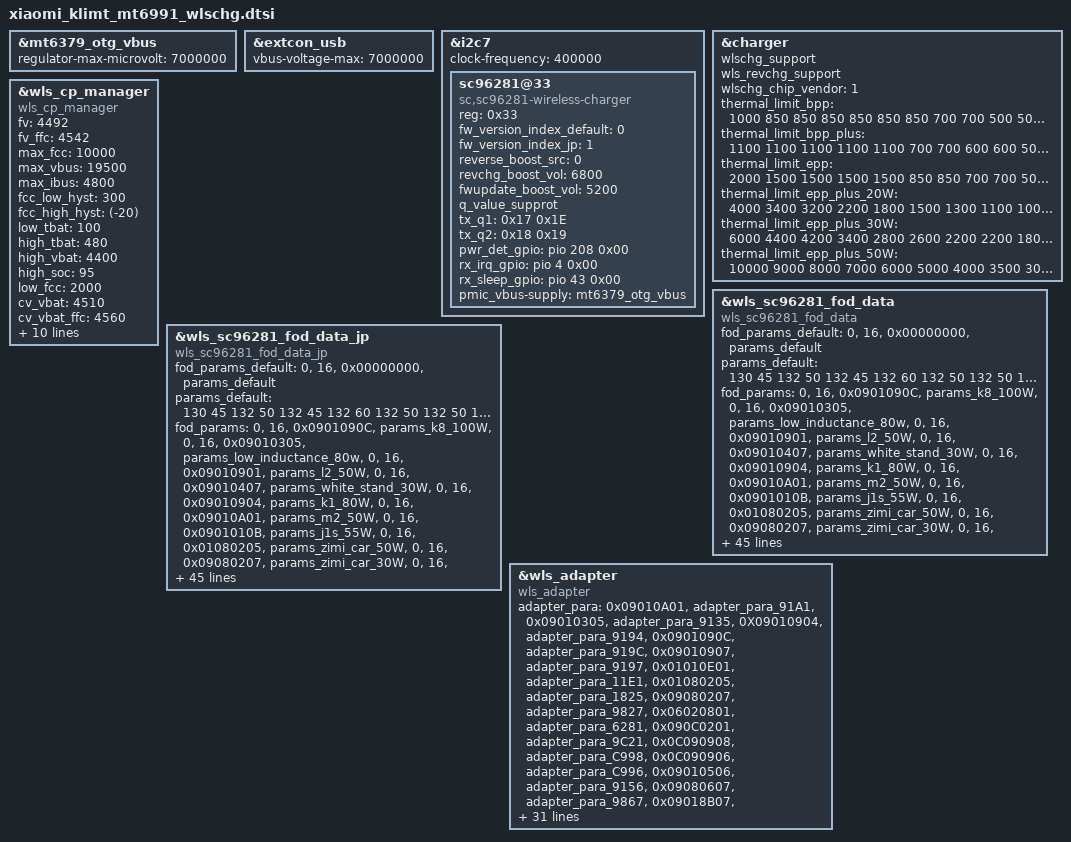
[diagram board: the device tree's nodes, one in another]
&mt6379_otg_vbus {
	regulator-max-microvolt = <7000000>;
};

&extcon_usb {
	vbus-voltage-max = <7000000>;
};

&i2c7 {
	clock-frequency = <400000>;
	sc96281@33{
		compatible = "sc,sc96281-wireless-charger";
		reg = <0x33>;
		fw_version_index_default = <0>;
		fw_version_index_jp = <1>;
		reverse_boost_src = <0>;
		revchg_boost_vol = <6800>;
		fwupdate_boost_vol = <5200>;
		q_value_supprot;
		tx_q1 = /bits/ 8 <0x17 0x1E>;
		tx_q2 = /bits/ 8 <0x18 0x19>;

		//support_hall = <0>;
		//rx_role = <0>;

		pwr_det_gpio = <&pio 208 0x00>;
		rx_irq_gpio = <&pio 4 0x00>;
		rx_sleep_gpio = <&pio 43 0x00>;
		pmic_vbus-supply = <&mt6379_otg_vbus>;
	};
};

&charger {
	wlschg_support;
	wls_revchg_support;
	wlschg_chip_vendor = <1>;
	/* wls thermal config */
	thermal_limit_bpp = <1000 850 850 850 850 850 850 700 700 500 500 500 500 500 400 300>;
	thermal_limit_bpp_plus = <1100 1100 1100 1100 1100 700 700 600 600 500 500 500 500 500 400 300>;
	thermal_limit_epp = <2000 1500 1500 1500 1500 850 850 700 700 500 500 500 500 500 400 300>;
	thermal_limit_epp_plus_20W = <4000 3400 3200 2200 1800 1500 1300 1100 1000 800 700 600 500 500 400 300>;
	thermal_limit_epp_plus_30W = <6000 4400 4200 3400 2800 2600 2200 2200 1800 1100 1000 800 700 600 500 400>;
	thermal_limit_epp_plus_50W = <10000 9000 8000 7000 6000 5000 4000 3500 3000 2500 2000 1500 1000 800 500 400>;
};

&wls_cp_manager {
	compatible = "wls_cp_manager";
	fv = <4492>;
	fv_ffc = <4542>;
	max_fcc = <10000>;
	max_vbus = <19500>;
	max_ibus = <4800>;
	fcc_low_hyst = <300>;
	fcc_high_hyst = <(-20)>;
	low_tbat = <100>;
	high_tbat = <480>;
	high_vbat = <4400>;
	high_soc = <95>;
	low_fcc = <2000>;
	cv_vbat = <4510>;
	cv_vbat_ffc = <4560>;
	cv_ibat = <1200>;
	vbus_low_gap_div = <500>;
	vbus_high_gap_div = <600>;
	wls_cm_ibus_gap = <600>;
	switch2_1_enter = <6000>;
	switch2_1_exit = <8000>;
	support_pmic_parachg;
	pmic_parachg_icl = <100>;
	max_curr_duration_4_1 = <240>;
	max_curr_duration_2_1 = <90>;
};

&wls_sc96281_fod_data {
	compatible = "wls_sc96281_fod_data";
	fod_params_default =
		"0", "16", "0x00000000", "params_default";
	params_default = /bits/ 8 <
		130  45
		132  50
		132  45
		132  60
		132  50
		132  50
		130  99
		130  99
		130  99
		130  99
		130  99
		130  99
		130  99
		130  99
		130  99
		130  99
	>;

	/* type, length, uuid, params */
	fod_params =
		"0", "16", "0x0901090C", "params_k8_100W",
		"0", "16", "0x09010305", "params_low_inductance_80w",
		"0", "16", "0x09010901", "params_l2_50W",
		"0", "16", "0x09010407", "params_white_stand_30W",
		"0", "16", "0x09010904", "params_k1_80W",
		"0", "16", "0x09010A01", "params_m2_50W",
		"0", "16", "0x0901010B", "params_j1s_55W",
		"0", "16", "0x01080205", "params_zimi_car_50W",
		"0", "16", "0x09080207", "params_zimi_car_30W",
		"0", "16", "0x09010907", "params_redmi_disc_30W",
		"0", "16", "0x09080108", "params_zimi_20W",
		"0", "16", "0x09010506", "params_moving_20W",
		"0", "16", "0x09010A07", "params_double_coil_30W",
		"0", "16", "0x06010101", "params_white_20W",
		"0", "16", "0x0C090908", "params_multcoil_20W",
		"0", "16", "0x06020801", "params_zimi_car_20W",
		"0", "16", "0x09080607", "params_bluetooth_30W",
		"0", "16", "0x07030801", "params_power_bank_30W";

	/* gain, offset */
	params_k8_100W = /bits/ 8 <
		120	50
		120	55
		121	55
		121	55
		121	65
		122	70
		122	80
		123	80
		125	85
		127	85
		255	127
		154	100
		144	80
		134	60
		134	60
		134	60
	>;

	params_low_inductance_80w = /bits/ 8 <
		118	45
		118	40
		118	40
		118	40
		118	40
		118	40
		119	40
		120	40
		120	40
		120	40
		115	30
		115	30
		115	30
		116	40
		117	40
		117	40
	>;

	params_l2_50W = /bits/ 8 <
		125	45
		125	45
		124	40
		124	55
		124	55
		124	55
		124	55
		123	50
		123	55
		123	55
		255	127
		154	100
		144	80
		134	60
		134	60
		134	60
	>;

	params_white_stand_30W = /bits/ 8 <
		125	65
		125	65
		125	60
		125	60
		125	60
		125	60
		125	70
		125	70
		125	70
		125	75
		255	127
		154	100
		144	80
		134	60
		134	60
		134	60
	>;

	params_k1_80W = /bits/ 8 <
		125	65
		125	65
		125	60
		125	60
		125	60
		125	60
		126	75
		128	75
		128	75
		129	75
		255	127
		154	100
		144	80
		134	60
		134	60
		134	60
	>;

	params_m2_50W = /bits/ 8 <
		125	55
		125	55
		124	50
		123	45
		123	40
		123	40
		122	40
		122	35
		121	35
		121	35
		253	127
		150	90
		140	60
		137	60
		137	60
		137	60
	>;

	params_j1s_55W = /bits/ 8 <
		125	45
		125	45
		125	50
		125	55
		125	60
		125	60
		124	55
		124	55
		124	55
		124	55
		255	127
		154	100
		144	80
		134	60
		134	60
		134	60
	>;

	params_zimi_car_50W = /bits/ 8 <
		120  25
		120  10
		120  15
		120  20
		102  19
		111  25
		123  25
		123  30
		129  15
		124  20
		126  20
		126  20
		112  40
		112  40
		112  40
		112  40
	>;

	params_zimi_car_30W = /bits/ 8 <
		128  40
		127  34
		127  34
		127  34
		126  34
		125  38
		125  38
		124  41
		124  43
		123  40
		126  36
		126  36
		128  40
		128  40
		128  40
		128  40
	>;

	params_redmi_disc_30W = /bits/ 8 <
		125	55
		125	55
		125	55
		125	55
		125	50
		125	50
		126	60
		127	55
		128	70
		129	70
		255	127
		154	100
		144	80
		134	60
		134	60
		134	60
	>;

	params_zimi_20W = /bits/ 8 <
		120  30
		124  45
		127  40
		127  40
		127  40
		127  40
		128  40
		127  40
		128  40
		128  40
		128  40
		128  40
		128  40
		128  40
		128  40
		128  40
	>;

	params_moving_20W = /bits/ 8 <
		122  30
		121  32
		123  22
		126  21
		126  27
		126  27
		122  24
		122  24
		122  24
		122  24
		122  24
		122  24
		122  24
		122  24
		122  24
		122  24
	>;

	params_double_coil_30W = /bits/ 8 <
		118	45
		118	45
		118	45
		118	35
		118	40
		118	40
		120	50
		121	60
		121	60
		121	60
		255	127
		154	100
		144	80
		134	60
		134	60
		134	60
	>;

	params_power_bank_30W = /bits/ 8 <
		120  25
		120  10
		120  15
		120  24
		102  29
		111  35
		123  35
		123  40
		129  25
		124  40
		126  40
		126  40
		112  40
		112  40
		112  40
		112  40
	>;

	params_white_20W = /bits/ 8 <
		120	50
		120	55
		121	55
		121	55
		121	65
		122	70
		122	80
		123	80
		125	85
		127	85
		255	127
		154	100
		144	80
		134	60
		134	60
		134	60
	>;

	params_multcoil_20W = /bits/ 8 <
		120  25
		120  10
		120  15
		120  20
		102  19
		111  25
		123  25
		123  30
		129  15
		124  20
		126  20
		126  20
		112  40
		112  40
		112  40
		112  40
	>;

	params_zimi_car_20W = /bits/ 8 <
		120  25
		120  10
		120  15
		120  20
		102  19
		111  25
		123  25
		123  30
		129  15
		124  20
		126  20
		126  20
		112  40
		112  40
		112  40
		112  40
	>;

	params_bluetooth_30W = /bits/ 8 <
		128  32
		138  40
		128  38
		125  37
		125  33
		126  40
		144  2
		129  40
		153  215
		149  222
		149  215
		127  40
		128  60
		128  60
		128  60
		128  60
	>;
};

&wls_sc96281_fod_data_jp {
	compatible = "wls_sc96281_fod_data_jp";
	fod_params_default =
		"0", "16", "0x00000000", "params_default";
	params_default = /bits/ 8 <
		130  45
		132  50
		132  45
		132  60
		132  50
		132  50
		130  99
		130  99
		130  99
		130  99
		130  99
		130  99
		130  99
		130  99
		130  99
		130  99
	>;

	/* type, length, uuid, params */
	fod_params =
		"0", "16", "0x0901090C", "params_k8_100W",
		"0", "16", "0x09010305", "params_low_inductance_80w",
		"0", "16", "0x09010901", "params_l2_50W",
		"0", "16", "0x09010407", "params_white_stand_30W",
		"0", "16", "0x09010904", "params_k1_80W",
		"0", "16", "0x09010A01", "params_m2_50W",
		"0", "16", "0x0901010B", "params_j1s_55W",
		"0", "16", "0x01080205", "params_zimi_car_50W",
		"0", "16", "0x09080207", "params_zimi_car_30W",
		"0", "16", "0x09010907", "params_redmi_disc_30W",
		"0", "16", "0x09080108", "params_zimi_20W",
		"0", "16", "0x09010506", "params_moving_20W",
		"0", "16", "0x09010A07", "params_double_coil_30W",
		"0", "16", "0x06010101", "params_white_20W",
		"0", "16", "0x0C090908", "params_multcoil_20W",
		"0", "16", "0x06020801", "params_zimi_car_20W",
		"0", "16", "0x09080607", "params_bluetooth_30W",
		"0", "16", "0x07030801", "params_power_bank_30W";

	/* gain, offset */
	params_k8_100W = /bits/ 8 <
		125	75
		125	75
		125	60
		125	60
		125	80
		125	80
		126	75
		128	75
		128	95
		129	95
		255	127
		154	100
		144	80
		134	60
		134	60
		134	60
	>;

	params_low_inductance_80w = /bits/ 8 <
		118	45
		118	40
		118	40
		118	40
		118	40
		119	45
		119	50
		120	50
		121	50
		122	50
		115	30
		115	30
		116	30
		118	40
		118	40
		118	40
	>;

	params_l2_50W = /bits/ 8 <
		125	65
		125	65
		124	60
		124	65
		124	65
		124	65
		124	65
		123	60
		123	65
		124	70
		253	127
		150	100
		140	80
		137	60
		137	60
		137	60
	>;

	params_white_stand_30W = /bits/ 8 <
		125	65
		125	65
		124	65
		124	65
		124	65
		124	70
		124	75
		124	80
		124	85
		124	80
		255	127
		154	100
		144	80
		134	60
		134	60
		134	60
	>;

	params_k1_80W = /bits/ 8 <
		125	75
		125	75
		125	60
		125	60
		125	80
		125	80
		126	95
		128	85
		128	95
		129	105
		255	127
		154	100
		144	80
		134	60
		134	60
		134	60
	>;

	params_m2_50W = /bits/ 8 <
		125	70
		125	70
		124	65
		123	55
		123	55
		123	55
		122	50
		122	45
		122	40
		122	40
		253	127
		150	90
		140	70
		140	70
		140	70
		140	70
	>;

	params_j1s_55W = /bits/ 8 <
		125	65
		125	65
		124	60
		124	65
		124	65
		124	65
		124	65
		124	70
		124	75
		124	80
		255	127
		154	100
		144	80
		134	60
		134	60
		134	60
	>;

	params_zimi_car_50W = /bits/ 8 <
		120  25
		120  10
		120  15
		120  20
		102  19
		111  25
		123  25
		123  30
		129  15
		124  20
		126  20
		126  20
		112  40
		112  40
		112  40
		112  40
	>;

	params_zimi_car_30W = /bits/ 8 <
		128  40
		127  34
		127  34
		127  34
		126  34
		125  38
		125  38
		124  41
		124  43
		123  40
		126  36
		126  36
		128  40
		128  40
		128  40
		128  40
	>;

	params_redmi_disc_30W = /bits/ 8 <
		125	55
		125	55
		125	55
		125	55
		125	50
		125	50
		126	60
		127	55
		128	70
		129	70
		255	127
		154	100
		144	80
		134	60
		134	60
		134	60
	>;

	params_zimi_20W = /bits/ 8 <
		120  30
		124  45
		127  40
		127  40
		127  40
		127  40
		128  40
		127  40
		128  40
		128  40
		128  40
		128  40
		128  40
		128  40
		128  40
		128  40
	>;

	params_moving_20W = /bits/ 8 <
		122  30
		121  32
		123  22
		126  21
		126  27
		126  27
		122  24
		122  24
		122  24
		122  24
		122  24
		122  24
		122  24
		122  24
		122  24
		122  24
	>;

	params_double_coil_30W = /bits/ 8 <
		125	45
		125	45
		124	40
		124	35
		124	35
		124	35
		124	35
		123	30
		121	25
		121	35
		255	127
		154	100
		144	80
		134	60
		134	60
		134	60
	>;

	params_power_bank_30W = /bits/ 8 <
		120  25
		120  10
		120  15
		120  24
		102  29
		111  35
		123  35
		123  40
		129  25
		124  40
		126  40
		126  40
		112  40
		112  40
		112  40
		112  40
	>;

	params_white_20W = /bits/ 8 <
		125	75
		125	75
		125	60
		125	60
		125	80
		125	80
		126	75
		128	75
		128	95
		129	95
		255	127
		154	100
		144	80
		134	60
		134	60
		134	60
	>;

	params_multcoil_20W = /bits/ 8 <
		120  25
		120  10
		120  15
		120  20
		102  19
		111  25
		123  25
		123  30
		129  15
		124  20
		126  20
		126  20
		112  40
		112  40
		112  40
		112  40
	>;

	params_zimi_car_20W = /bits/ 8 <
		120  25
		120  10
		120  15
		120  20
		102  19
		111  25
		123  25
		123  30
		129  15
		124  20
		126  20
		126  20
		112  40
		112  40
		112  40
		112  40
	>;

	params_bluetooth_30W = /bits/ 8 <
		128  32
		138  40
		128  38
		125  37
		125  33
		126  40
		144  2
		129  40
		153  215
		149  222
		149  215
		127  40
		128  60
		128  60
		128  60
		128  60
	>;
};

&wls_adapter {
	compatible = "wls_adapter";

	adapter_para =
		"0x09010A01", "adapter_para_91A1",	/* XIAOMI_TX_UUID_LOW_INDUCTANCE_50W */
		"0x09010305", "adapter_para_9135",	/* XIAOMI_TX_UUID_LOW_INDUCTANCE_80W */
		"0X09010904", "adapter_para_9194",	/* XIAOMI_TX_UUID_SAILBOAT_80W */
		"0x0901090C", "adapter_para_919C",	/* XIAOMI_TX_UUID_SAILBOAT_100W */
		"0x09010907", "adapter_para_9197",	/* XIAOMI_TX_UUID_REDMI_30W */
		"0x01010E01", "adapter_para_11E1",	/* XIAOMI_TX_UUID_TRAIN_20W */
		"0x01080205", "adapter_para_1825",	/* XIAOMI_TX_UUID_ZIMI_CAR_50W */
		"0x09080207", "adapter_para_9827",	/* XIAOMI_TX_UUID_ZIMI_CAR_30W */
		"0x06020801", "adapter_para_6281",	/* XIAOMI_TX_UUID_ZIMI_CAR_20W */
		"0x090C0201", "adapter_para_9C21",	/* XIAOMI_TX_UUID_KUKE_CAR_50W */
		"0x0C090908", "adapter_para_C998",	/* XIAOMI_TX_UUID_MULTI_COIL2_20W */
		"0x0C090906", "adapter_para_C996",	/* XIAOMI_TX_UUID_MULTI_COIL_20W */
		"0x09010506", "adapter_para_9156",	/* XIAOMI_TX_UUID_MOVING_PLATE_20W */
		"0x09080607", "adapter_para_9867",	/* XIAOMI_TX_UUID_MUSICAL_BOX_30W */
		"0x09018B07", "adapter_para_918B7";	/* XIAOMI_TX_UUID_MAGNET_30W */

	/* standard_tx, musical_box, plate_tx, car_mounted, train_tx, redmi_30w_tx, sailboat_tx, low_inductance_50w_tx, low_inductance_80w_tx, support_fan, magnet_tx*/
	adapter_para_91A1 = "1", "0", "0", "0", "0", "0", "0", "1", "0", "1", "0";
	adapter_para_9135 = "0", "0", "0", "0", "0", "0", "0", "0", "1", "1", "0";
	adapter_para_9194 = "0", "0", "0", "0", "0", "0", "1", "0", "0", "1", "0";
	adapter_para_919C = "0", "0", "0", "0", "0", "0", "1", "0", "0", "1", "0";
	adapter_para_9197 = "0", "0", "0", "0", "0", "1", "0", "0", "0", "1", "0";
	adapter_para_11E1 = "0", "0", "0", "0", "1", "0", "0", "0", "0", "0", "0";
	adapter_para_1825 = "0", "0", "0", "1", "0", "0", "0", "0", "0", "0", "0";
	adapter_para_9827 = "0", "0", "0", "1", "0", "0", "0", "0", "0", "0", "0";
	adapter_para_6281 = "0", "0", "0", "1", "0", "0", "0", "0", "0", "0", "0";
	adapter_para_9C21 = "0", "0", "0", "1", "0", "0", "0", "0", "0", "0", "0";
	adapter_para_C998 = "0", "0", "1", "0", "0", "0", "0", "0", "0", "0", "0";
	adapter_para_C996 = "0", "0", "1", "0", "0", "0", "0", "0", "0", "0", "0";
	adapter_para_9156 = "0", "0", "1", "0", "0", "0", "0", "0", "0", "0", "0";
	adapter_para_9867 = "0", "1", "0", "0", "0", "0", "0", "0", "0", "0", "0";
	adapter_para_918B7 = "0", "0", "0", "0", "0", "0", "0", "0", "0", "0", "1";
};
